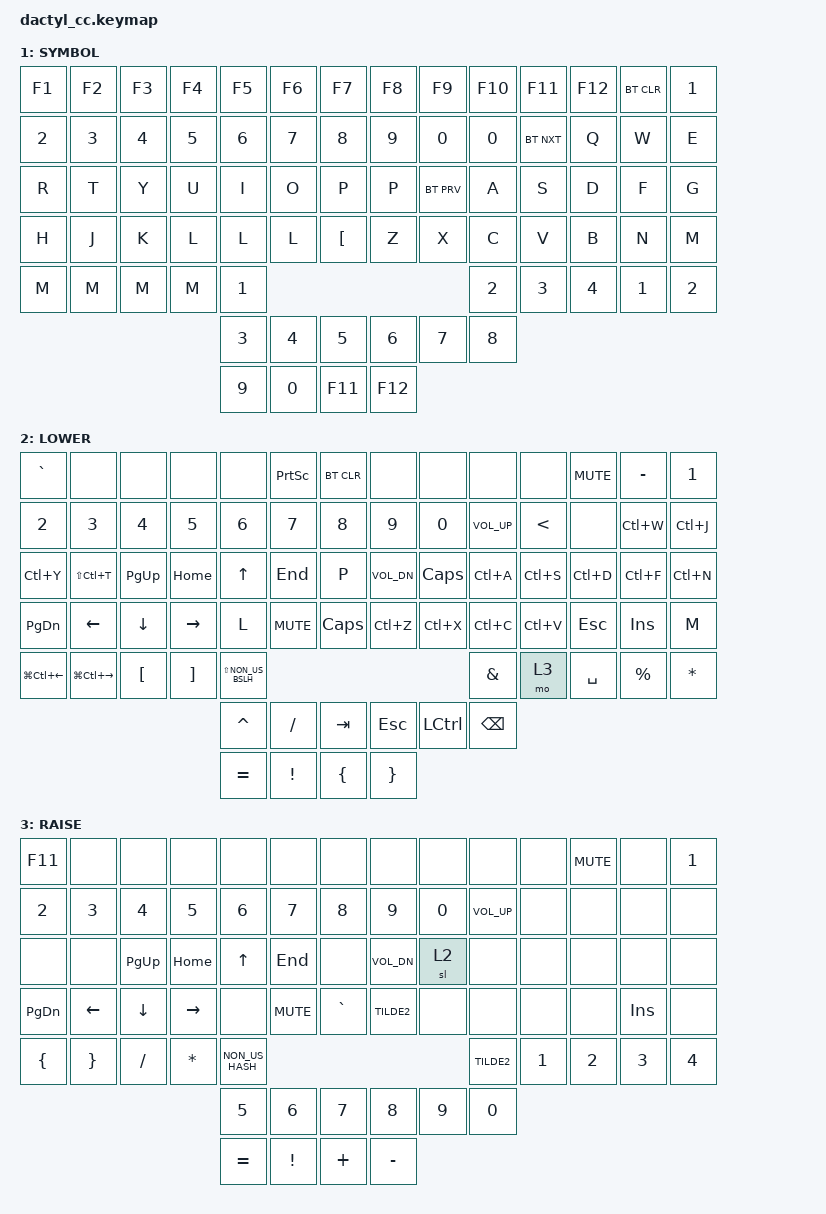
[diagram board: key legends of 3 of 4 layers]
#include <behaviors.dtsi>
#include <dt-bindings/zmk/bt.h>
#include <dt-bindings/zmk/keys.h>

// #############         LAYERS         #################

#define SYM_L   1
#define NAV_L   2
#define NAV2_L  3

//#define OTHER_L 4

#define DEFAULT 0
#define LOWER   1
#define RAISE   2
#define SYMBOL  3

// Desktop and tab navigation shortcuts		

#define DESKTOP_LT   LC(LG(LEFT))
#define DESKTOP_RT   LC(LG(RIGHT))
#define WINDOW_LT    LA(LS(TAB))
#define WINDOW_RT    LA(TAB)
#define TAB_LT       LC(LS(TAB))
#define TAB_RT       LC(TAB)

// NOT USED  &kp LG(LC(LEFT))  &kp LG(LC(RIGHT))
// Generic bindings

#define KILL_WINDOW  LA(F4)
#define MAXIMIZE     LG(UP)
#define MINIMIZE     LG(DOWN)
#define UN_MINIMIZE  LG(LC(N))

&mt {
    flavor = "hold-preferred";
    tapping-term-ms = <500>;
};

&lt {
    flavor = "balanced";
    tapping-term-ms = <150>;
};

&sl {
    release-after-ms = <2000>;
};

/ {
    conditional_layers {
        compatible = "zmk,conditional-layers";

        tri_layer {
            if-layers = <3 4>;
            then-layer = <0>;
        };
    };

    macros {
        ZMK_MACRO(inv_qm,

        wait-ms = <10>;
        tap-ms = <10>;
        bindings =
            <&macro_press &kp LALT>,
            <&macro_tap &kp KP_N1 &kp KP_N6 &kp KP_N8>,
            <&macro_release &kp LALT>;

        )
    };

    behaviors {
        //   td_mt_ls: tap_dance_mod_tap {
        //       compatible = "zmk,behavior-tap-dance";
        //       label = "TAP_DANCE_LSHIFT";
        //       #binding-cells = <0>;
        //       tapping-term-ms = <200>;
        //       bindings = <&mt LSHIFT CAPSLOCK>, <&kp LCTRL>;
        //   };
        //   td_mt_rs: tap_dance_mod_tap {
        //       compatible = "zmk,behavior-tap-dance";
        //       label = "TAP_DANCE_RSHIFT";
        //       #binding-cells = <0>;
        //       tapping-term-ms = <200>;
        //       bindings = <&mt RSHIFT CAPSLOCK>, <&kp RCTRL>;
        //   };            
    };

    keymap {
        compatible = "zmk,keymap";


        default_layer {
            bindings = <
&kp ESCAPE    &kp N1    &kp N2   &kp N3    &kp N4    &kp N5  &kp N6                  &kp N7      &kp N8    &kp N9    &kp N0    &kp MINUS  &kp EQUAL  &kp BACKSPACE     
&kp TAB       &kp Q     &kp W    &kp E     &kp R     &kp T   &kp LBKT                &kp RBKT    &kp Y     &kp U     &kp I     &kp O      &kp P      &kp RBKT
&kp CAPS      &kp A     &kp S    &kp D     &kp F     &kp G   &kp GRAVE               &kp APOS    &kp H     &kp J     &kp K     &kp L      &kp SEMI   &kp KP_ENTER
&kp LSHFT     &kp Z     &kp X    &kp C     &kp V     &kp B   &kp C_PP                &kp C_MUTE  &kp N     &kp M     &kp COMMA &kp DOT    &kp FSLH   &kp RSHFT
&kp LCTRL     &kp LGUI  &mo 1    &kp LALT  &kp PG_UP                                                       &kp PG_DN &kp LEFT   &kp UP    &kp DOWN   &kp RIGHT
                                         &kp EQUAL   &kp MINUS    &kp SPACE               &mo LBKT  &kp RBKT         &kp C_MUTE
                                         &kp GRAVE   &kp BSPC     &kp SPACE               &kp BACKSPACE &kp KP_ENTER &mo 1
            >;
        };

        SYMBOL {
            bindings = <
&kp F1  &kp F2  &kp F3  &kp F4  &kp F5  &kp F6  &kp F7      &kp F8   &kp F9      &kp F10  &kp F11     &kp F12  &bt BT_CLR  &kp N1
&kp N2  &kp N3  &kp N4  &kp N5  &kp N6  &kp N7  &kp N8      &kp N9   &kp N0      &kp N0   &bt BT_NXT  &kp Q    &kp W       &kp E
&kp R   &kp T   &kp Y   &kp U   &kp I   &kp O   &kp P       &kp P    &bt BT_PRV  &kp A    &kp S       &kp D    &kp F       &kp G
&kp H   &kp J   &kp K   &kp L   &kp L   &kp L   &kp LBKT    &kp Z    &kp X       &kp C    &kp V       &kp B    &kp N       &kp M
&kp M   &kp M   &kp M   &kp M   &kp N1                                           &kp N2   &kp N3      &kp N4   &kp N1      &kp N2
                                &kp N3  &kp N4  &kp N5      &kp N6   &kp N7      &kp N8
                                &kp N9  &kp N0  &kp F11     &kp F12
            >;
        };

        LOWER {
            bindings = <
&kp GRAVE         &none              &none      &none      &none                &kp PSCRN   &bt BT_CLR    &none         &none      &none         &none      &kp C_MUTE  &kp MINUS  &kp N1
&kp N2            &kp N3             &kp N4     &kp N5     &kp N6               &kp N7      &kp N8        &kp N9        &kp N0     &kp C_VOL_UP  &kp LT     &none       &kp LC(W)  &kp LC(J)
&kp LC(Y)         &kp LS(LC(T))      &kp PG_UP  &kp HOME   &kp UP               &kp END     &kp P         &kp C_VOL_DN  &kp CAPS   &kp LC(A)     &kp LC(S)  &kp LC(D)   &kp LC(F)  &kp LC(N)
&kp PG_DN         &kp LEFT           &kp DOWN   &kp RIGHT  &kp L                &kp C_MUTE  &kp CAPS      &kp LC(Z)     &kp LC(X)  &kp LC(C)     &kp LC(V)  &kp ESC     &kp INS    &kp M
&kp LG(LC(LEFT))  &kp LG(LC(RIGHT))  &kp LBKT   &kp RBKT   &kp LS(NON_US_BSLH)                                                     &kp AMPS      &mo 3      &kp SPACE   &kp PRCNT  &kp ASTRK
                                                           &kp CARET            &kp FSLH    &kp TAB       &kp ESC       &kp LCTRL  &kp BSPC
                                                           &kp EQUAL            &kp EXCL    &kp LBRC      &kp RBRC
            >;
        };

        RAISE {
            bindings = <
&kp F11    &none     &none      &none      &none            &none       &none        &none         &none   &none         &none   &kp C_MUTE  &none    &kp N1
&kp N2     &kp N3    &kp N4     &kp N5     &kp N6           &kp N7      &kp N8       &kp N9        &kp N0  &kp C_VOL_UP  &none   &none       &none    &none
&none      &none     &kp PG_UP  &kp HOME   &kp UP           &kp END     &none        &kp C_VOL_DN  &sl 2   &none         &none   &none       &none    &none
&kp PG_DN  &kp LEFT  &kp DOWN   &kp RIGHT  &none            &kp C_MUTE  &kp GRAVE    &kp TILDE2    &none   &none         &none   &none       &kp INS  &none
&kp LBRC   &kp RBRC  &kp FSLH   &kp ASTRK  &kp NON_US_HASH                                                 &kp TILDE2    &kp N1  &kp N2      &kp N3   &kp N4
                                           &kp N5           &kp N6      &kp N7       &kp N8        &kp N9  &kp N0
                                           &kp EQUAL        &kp EXCL    &kp PLUS     &kp MINUS
            >;
        };
    };
};
